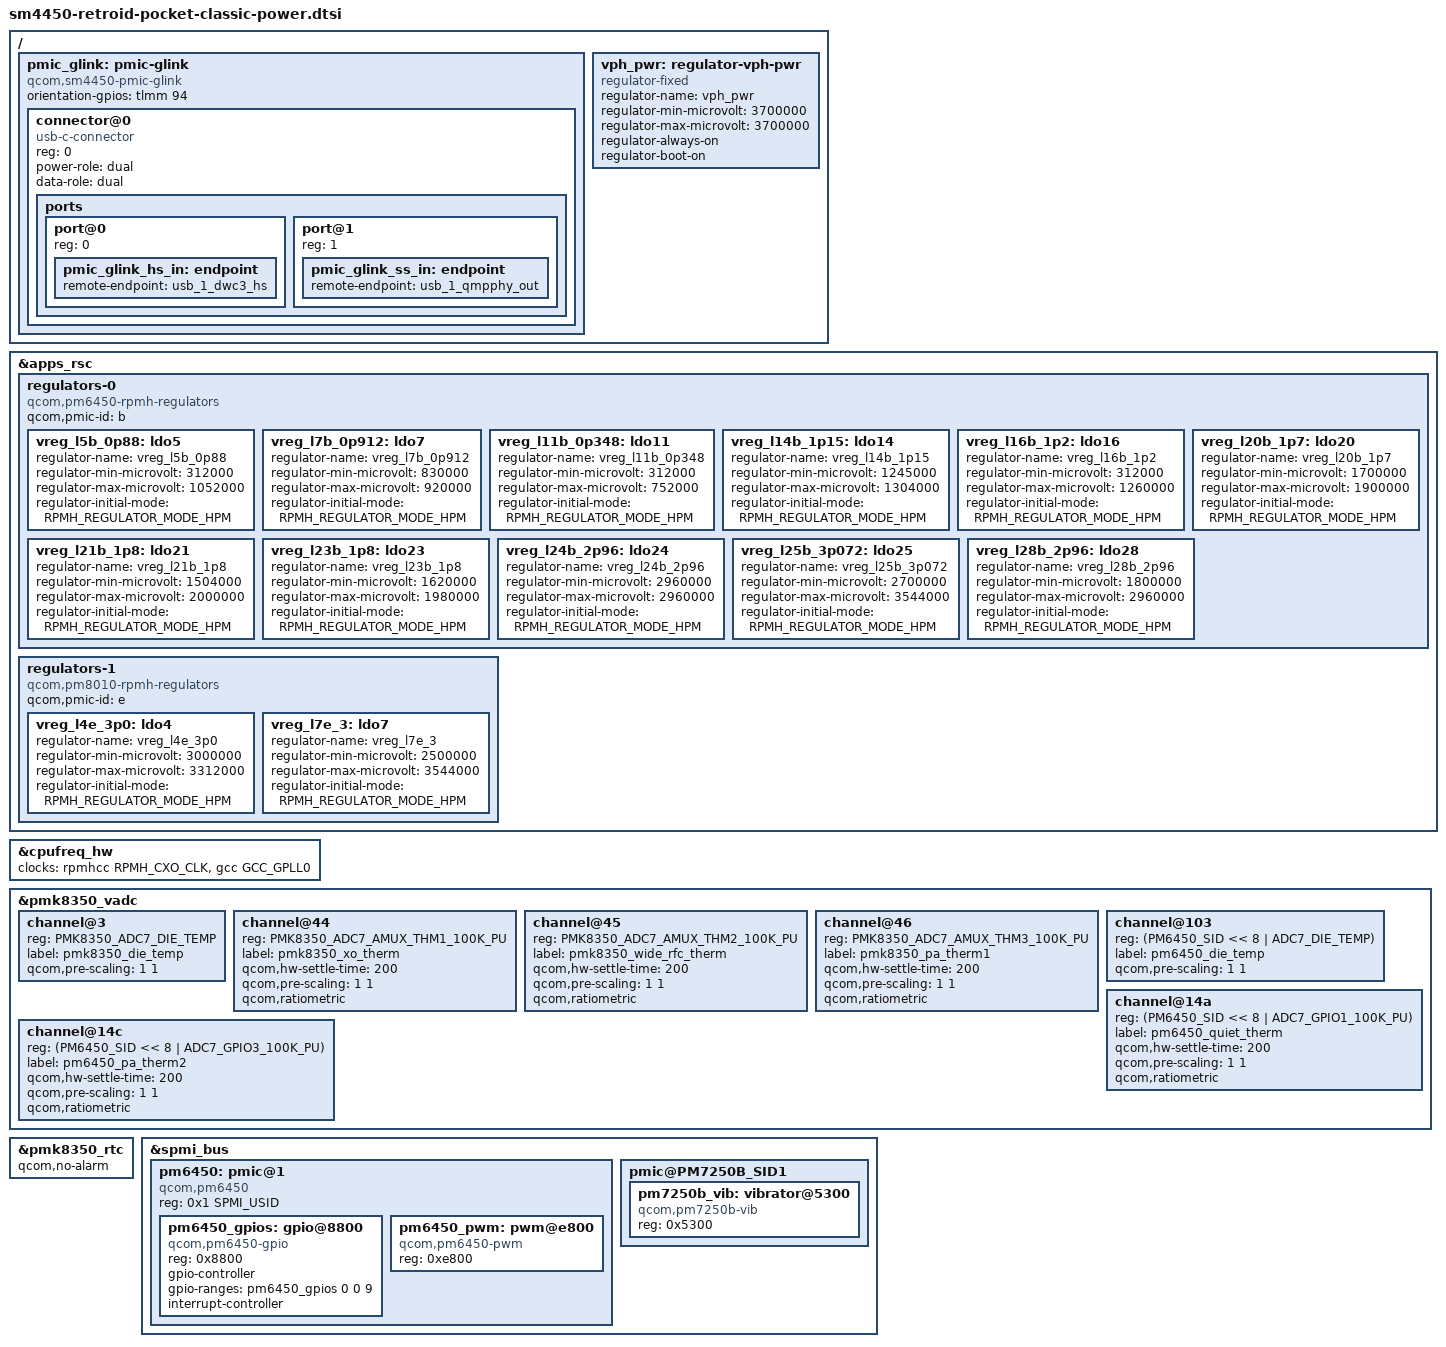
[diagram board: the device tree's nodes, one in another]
// SPDX-License-Identifier: BSD-3-Clause
/*
 * Copyright (C) 2026-present ROCKNIX (https://github.com/ROCKNIX).
 *
 * Retroid Pocket Classic (SM4450 "parrot"): power.
 * Maintained by Banana as its own description of this handheld (it started as ROCKNIX's tree).
 *
 * PMIC regulators, the battery and charger (through pmic_glink to the ADSP), the PMICs on SPMI
 * with their ADC channels and RTC, and CPU frequency scaling.
 *
 * Included from sm4450-retroid-pocket-classic-common.dtsi; do not include it on its own.
 */

/* ---- Battery, charger and USB-C role, reported by the ADSP over pmic_glink ---- */

/ {
	pmic_glink: pmic-glink {
		compatible = "qcom,sm4450-pmic-glink", "qcom,pmic-glink";
		#address-cells = <1>;
		#size-cells = <0>;
		orientation-gpios = <&tlmm 94 GPIO_ACTIVE_HIGH>;
		status = "okay";

		connector@0 {
			compatible = "usb-c-connector";
			reg = <0>;
			power-role = "dual";
			data-role = "dual";

			ports {
				#address-cells = <1>;
				#size-cells = <0>;

				port@0 {
					reg = <0>;

					pmic_glink_hs_in: endpoint {
						remote-endpoint = <&usb_1_dwc3_hs>;
					};
				};

				port@1 {
					reg = <1>;

					pmic_glink_ss_in: endpoint {
						remote-endpoint = <&usb_1_qmpphy_out>;
					};
				};
			};
		};
	};

	vph_pwr: regulator-vph-pwr {
		compatible = "regulator-fixed";
		regulator-name = "vph_pwr";
		regulator-min-microvolt = <3700000>;
		regulator-max-microvolt = <3700000>;
		regulator-always-on;
		regulator-boot-on;
	};
};

/* ---- RPMh regulators on PM6450 ("b") and the "e" PMIC (pm8010 register layout)
 * Only rails something in this tree consumes are listed (the rest showed 0 users on the device and
 * Linux never enabled them; listing them only cast an HPM mode vote). ---- */

&apps_rsc {
	/* Voltage constraints extracted from the live parrot (RP Classic) DT */
	regulators-0 {
		compatible = "qcom,pm6450-rpmh-regulators";
		qcom,pmic-id = "b";
		vreg_l5b_0p88: ldo5 {
			regulator-name = "vreg_l5b_0p88";
			regulator-min-microvolt = <312000>;
			regulator-max-microvolt = <1052000>;
			regulator-initial-mode = <RPMH_REGULATOR_MODE_HPM>;
		};
		vreg_l7b_0p912: ldo7 {
			regulator-name = "vreg_l7b_0p912";
			regulator-min-microvolt = <830000>;
			regulator-max-microvolt = <920000>;
			regulator-initial-mode = <RPMH_REGULATOR_MODE_HPM>;
		};
		vreg_l11b_0p348: ldo11 {
			regulator-name = "vreg_l11b_0p348";
			regulator-min-microvolt = <312000>;
			regulator-max-microvolt = <752000>;
			regulator-initial-mode = <RPMH_REGULATOR_MODE_HPM>;
		};
		vreg_l14b_1p15: ldo14 {
			regulator-name = "vreg_l14b_1p15";
			regulator-min-microvolt = <1245000>;
			regulator-max-microvolt = <1304000>;
			regulator-initial-mode = <RPMH_REGULATOR_MODE_HPM>;
		};
		vreg_l16b_1p2: ldo16 {
			regulator-name = "vreg_l16b_1p2";
			regulator-min-microvolt = <312000>;
			regulator-max-microvolt = <1260000>;
			regulator-initial-mode = <RPMH_REGULATOR_MODE_HPM>;
		};
		vreg_l20b_1p7: ldo20 {
			regulator-name = "vreg_l20b_1p7";
			regulator-min-microvolt = <1700000>;
			regulator-max-microvolt = <1900000>;
			regulator-initial-mode = <RPMH_REGULATOR_MODE_HPM>;
		};
		vreg_l21b_1p8: ldo21 {
			regulator-name = "vreg_l21b_1p8";
			regulator-min-microvolt = <1504000>;
			regulator-max-microvolt = <2000000>;
			regulator-initial-mode = <RPMH_REGULATOR_MODE_HPM>;
		};
		vreg_l23b_1p8: ldo23 {
			regulator-name = "vreg_l23b_1p8";
			regulator-min-microvolt = <1620000>;
			regulator-max-microvolt = <1980000>;
			regulator-initial-mode = <RPMH_REGULATOR_MODE_HPM>;
		};
		vreg_l24b_2p96: ldo24 {
			regulator-name = "vreg_l24b_2p96";
			regulator-min-microvolt = <2960000>;
			regulator-max-microvolt = <2960000>;
			regulator-initial-mode = <RPMH_REGULATOR_MODE_HPM>;
		};
		vreg_l25b_3p072: ldo25 {
			regulator-name = "vreg_l25b_3p072";
			regulator-min-microvolt = <2700000>;
			regulator-max-microvolt = <3544000>;
			regulator-initial-mode = <RPMH_REGULATOR_MODE_HPM>;
		};
		vreg_l28b_2p96: ldo28 {
			regulator-name = "vreg_l28b_2p96";
			regulator-min-microvolt = <1800000>;
			regulator-max-microvolt = <2960000>;
			regulator-initial-mode = <RPMH_REGULATOR_MODE_HPM>;
		};
	};

	regulators-1 {
		compatible = "qcom,pm8010-rpmh-regulators";
		qcom,pmic-id = "e";
		vreg_l4e_3p0: ldo4 {
			regulator-name = "vreg_l4e_3p0";
			regulator-min-microvolt = <3000000>;
			regulator-max-microvolt = <3312000>;
			regulator-initial-mode = <RPMH_REGULATOR_MODE_HPM>;
		};
		vreg_l7e_3: ldo7 {
			regulator-name = "vreg_l7e_3";
			regulator-min-microvolt = <2500000>;
			regulator-max-microvolt = <3544000>;
			regulator-initial-mode = <RPMH_REGULATOR_MODE_HPM>;
		};
	};
};

&cpufreq_hw {
	clocks = <&rpmhcc RPMH_CXO_CLK>, <&gcc GCC_GPLL0>;
};

/* ---- PMICs on SPMI ---- */

#define PMK8350_SID 0
#define PM6450_SID 1
#define PM7250B_SID 8
#define PM7250B_SID1 9
#include "pmk8350.dtsi"
#include "pm7250b.dtsi"

&pmk8350_vadc {
	channel@3 {
		reg = <PMK8350_ADC7_DIE_TEMP>;
		label = "pmk8350_die_temp";
		qcom,pre-scaling = <1 1>;
	};

	channel@44 {
		reg = <PMK8350_ADC7_AMUX_THM1_100K_PU>;
		label = "pmk8350_xo_therm";
		qcom,hw-settle-time = <200>;
		qcom,pre-scaling = <1 1>;
		qcom,ratiometric;
	};

	channel@45 {
		reg = <PMK8350_ADC7_AMUX_THM2_100K_PU>;
		label = "pmk8350_wide_rfc_therm";
		qcom,hw-settle-time = <200>;
		qcom,pre-scaling = <1 1>;
		qcom,ratiometric;
	};

	channel@46 {
		reg = <PMK8350_ADC7_AMUX_THM3_100K_PU>;
		label = "pmk8350_pa_therm1";
		qcom,hw-settle-time = <200>;
		qcom,pre-scaling = <1 1>;
		qcom,ratiometric;
	};

	/* PM6450 channels are read through the PMK8350 ADC (SID-encoded) */
	channel@103 {
		reg = <(PM6450_SID << 8 | ADC7_DIE_TEMP)>;
		label = "pm6450_die_temp";
		qcom,pre-scaling = <1 1>;
	};

	channel@14a {
		reg = <(PM6450_SID << 8 | ADC7_GPIO1_100K_PU)>;
		label = "pm6450_quiet_therm";
		qcom,hw-settle-time = <200>;
		qcom,pre-scaling = <1 1>;
		qcom,ratiometric;
	};

	channel@14c {
		reg = <(PM6450_SID << 8 | ADC7_GPIO3_100K_PU)>;
		label = "pm6450_pa_therm2";
		qcom,hw-settle-time = <200>;
		qcom,pre-scaling = <1 1>;
		qcom,ratiometric;
	};
};

&pmk8350_rtc {
	/* TODO: will need nvmem region */
	/* The RTC alarm interrupt is not the OS's on these Qualcomm PMICs (it is the ADSP's -- as annotated on hamoa and
	 * glymur), so Linux gets no wakealarm and bananad's sleep_check_hours cannot fire. Do NOT drop this to "fix" the
	 * battery check: the alarm IRQ belongs to the ADSP, so requesting it only arms an interrupt that never arrives.
	 * bananad instead refuses to sleep a low battery when there is no wakealarm (sleep_floor_percent). */
	qcom,no-alarm;
	status = "okay";
};

&spmi_bus {
	pm6450: pmic@1 {
		compatible = "qcom,pm6450", "qcom,spmi-pmic";
		reg = <0x1 SPMI_USID>;
		#address-cells = <1>;
		#size-cells = <0>;

		pm6450_gpios: gpio@8800 {
			compatible = "qcom,pm6450-gpio", "qcom,spmi-gpio";
			reg = <0x8800>;
			gpio-controller;
			gpio-ranges = <&pm6450_gpios 0 0 9>;
			#gpio-cells = <2>;
			interrupt-controller;
			#interrupt-cells = <2>;

		};

		pm6450_pwm: pwm@e800 {
			compatible = "qcom,pm6450-pwm";
			reg = <0xe800>;	/* one LPG channel; stock DT qcom,pwms@e800 */
			#pwm-cells = <2>;
		};
	};

	pmic@PM7250B_SID1 {
		pm7250b_vib: vibrator@5300 {
			compatible = "qcom,pm7250b-vib", "qcom,pmi632-vib";
			reg = <0x5300>;
		};
	};
};
